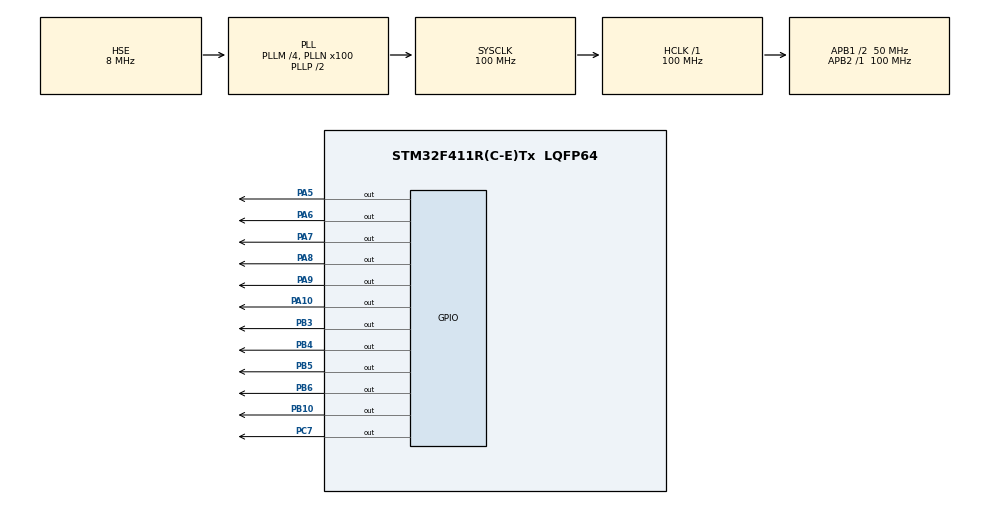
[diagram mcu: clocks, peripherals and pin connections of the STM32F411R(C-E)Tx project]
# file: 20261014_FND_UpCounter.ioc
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Mcu.Family=STM32F4
Mcu.Name=STM32F411R(C-E)Tx
Mcu.Package=LQFP64
NVIC.PriorityGroup=NVIC_PRIORITYGROUP_4
PA10.Signal=GPIO_Output
PA5.Signal=GPIO_Output
PA6.Signal=GPIO_Output
PA7.Signal=GPIO_Output
PA8.Signal=GPIO_Output
PA9.Signal=GPIO_Output
PB10.Signal=GPIO_Output
PB3.Signal=GPIO_Output
PB4.Signal=GPIO_Output
PB5.Signal=GPIO_Output
PB6.Signal=GPIO_Output
PC7.Signal=GPIO_Output
PH0\ -\ OSC_IN.Mode=HSE-External-Oscillator
PH0\ -\ OSC_IN.Signal=RCC_OSC_IN
PH1\ -\ OSC_OUT.Mode=HSE-External-Oscillator
PH1\ -\ OSC_OUT.Signal=RCC_OSC_OUT
ProjectManager.HeapSize=0x200
ProjectManager.StackSize=0x400
ProjectManager.TargetToolchain=STM32CubeIDE
RCC.48MHZClocksFreq_Value=50000000
RCC.AHBFreq_Value=100000000
RCC.APB1CLKDivider=RCC_HCLK_DIV2
RCC.APB1Freq_Value=50000000
RCC.APB1TimFreq_Value=100000000
RCC.APB2Freq_Value=100000000
RCC.APB2TimFreq_Value=100000000
RCC.CortexFreq_Value=100000000
RCC.HCLKFreq_Value=100000000
RCC.HSE_VALUE=8000000
RCC.HSI_VALUE=16000000
RCC.LSE_VALUE=32768
RCC.PLLM=4
RCC.PLLN=100
RCC.PLLSourceVirtual=RCC_PLLSOURCE_HSE
RCC.SYSCLKFreq_VALUE=100000000
RCC.SYSCLKSource=RCC_SYSCLKSOURCE_PLLCLK
RCC.VCOOutputFreq_Value=200000000
board=custom

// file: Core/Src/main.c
/* USER CODE BEGIN Header */
/**
 ******************************************************************************
 * @file           : main.c
 * @brief          : Main program body
 ******************************************************************************
 * @attention
 *
 * Copyright (c) 2026 STMicroelectronics.
 * All rights reserved.
 *
 * This software is licensed under terms that can be found in the LICENSE file
 * in the root directory of this software component.
 * If no LICENSE file comes with this software, it is provided AS-IS.
 *
 ******************************************************************************
 */
/* USER CODE END Header */
#include "main.h"

/* USER CODE BEGIN Includes */
#include "driver/fnd/fnd.h"
/* USER CODE END Includes */

void SystemClock_Config(void);
static void MX_GPIO_Init(void);

int main(void)
{

	/* USER CODE BEGIN 1 */

	/*
	seg_port_t seg_font[8] = {

			{GPIOA, GPIO_PIN_6},
			{GPIOA, GPIO_PIN_9},
			{GPIOB, GPIO_PIN_5},
			{GPIOB, GPIO_PIN_10},
			{GPIOA, GPIO_PIN_8},
			{GPIOA, GPIO_PIN_7},
			{GPIOB, GPIO_PIN_3},
			{GPIOB, GPIO_PIN_4}
	};

	int seg_font_data[10][8] = {
			{1, 1, 1, 1, 1, 1, 0, 0}, // 0
			{0, 1, 1, 0, 0, 0, 0, 0}, // 1
			{1, 1, 0, 1, 1, 0, 1, 0}, // 2
			{1, 1, 1, 1, 0, 0, 1, 0}, // 3
			{0, 1, 1, 0, 0, 1, 1, 0}, // 4
			{1, 0, 1, 1, 0, 1, 1, 0}, // 5
			{1, 0, 1, 1, 1, 1, 1, 0}, // 6
			{1, 1, 1, 0, 0, 0, 0, 0}, // 7
			{1, 1, 1, 1, 1, 1, 1, 0}, // 8
			{1, 1, 1, 1, 0, 1, 1, 0}, // 9
	};
	*/

	/* USER CODE END 1 */

	/* MCU Configuration--------------------------------------------------------*/

	/* Reset of all peripherals, Initializes the Flash interface and the Systick. */
	HAL_Init();

	/* Configure the system clock */
	SystemClock_Config();

	/* Initialize all configured peripherals */
	MX_GPIO_Init();

	/* Infinite loop */
	/* USER CODE BEGIN WHILE */
	uint16_t counter = 0;
	uint32_t prevTime = 0;

	while (1)
	{
		fnd_show_number(counter);

		if (HAL_GetTick() - prevTime > 100 ){
			prevTime = HAL_GetTick();

			if (counter == 9999) {
				counter = 0;
			}
			else {
				counter++;
			}
		}

		/* USER CODE END WHILE */

	}
}

void SystemClock_Config(void)
{
	RCC_OscInitTypeDef RCC_OscInitStruct = {0};
	RCC_ClkInitTypeDef RCC_ClkInitStruct = {0};

	/** Configure the main internal regulator output voltage
	 */
	__HAL_RCC_PWR_CLK_ENABLE();
	__HAL_PWR_VOLTAGESCALING_CONFIG(PWR_REGULATOR_VOLTAGE_SCALE1);

	/** Initializes the RCC Oscillators according to the specified parameters
	 * in the RCC_OscInitTypeDef structure.
	 */
	RCC_OscInitStruct.OscillatorType = RCC_OSCILLATORTYPE_HSE;
	RCC_OscInitStruct.HSEState = RCC_HSE_ON;
	RCC_OscInitStruct.PLL.PLLState = RCC_PLL_ON;
	RCC_OscInitStruct.PLL.PLLSource = RCC_PLLSOURCE_HSE;
	RCC_OscInitStruct.PLL.PLLM = 4;
	RCC_OscInitStruct.PLL.PLLN = 100;
	RCC_OscInitStruct.PLL.PLLP = RCC_PLLP_DIV2;
	RCC_OscInitStruct.PLL.PLLQ = 4;
	if (HAL_RCC_OscConfig(&RCC_OscInitStruct) != HAL_OK)
	{
		Error_Handler();
	}

	/** Initializes the CPU, AHB and APB buses clocks
	 */
	RCC_ClkInitStruct.ClockType = RCC_CLOCKTYPE_HCLK|RCC_CLOCKTYPE_SYSCLK
			|RCC_CLOCKTYPE_PCLK1|RCC_CLOCKTYPE_PCLK2;
	RCC_ClkInitStruct.SYSCLKSource = RCC_SYSCLKSOURCE_PLLCLK;
	RCC_ClkInitStruct.AHBCLKDivider = RCC_SYSCLK_DIV1;
	RCC_ClkInitStruct.APB1CLKDivider = RCC_HCLK_DIV2;
	RCC_ClkInitStruct.APB2CLKDivider = RCC_HCLK_DIV1;

	if (HAL_RCC_ClockConfig(&RCC_ClkInitStruct, FLASH_LATENCY_3) != HAL_OK)
	{
		Error_Handler();
	}
}

static void MX_GPIO_Init(void)
{
	GPIO_InitTypeDef GPIO_InitStruct = {0};

	/* GPIO Ports Clock Enable */
	__HAL_RCC_GPIOH_CLK_ENABLE();
	__HAL_RCC_GPIOA_CLK_ENABLE();
	__HAL_RCC_GPIOB_CLK_ENABLE();
	__HAL_RCC_GPIOC_CLK_ENABLE();

	/*Configure GPIO pin Output Level */
	HAL_GPIO_WritePin(GPIOA, GPIO_PIN_5|GPIO_PIN_6|GPIO_PIN_7|GPIO_PIN_8
			|GPIO_PIN_9|GPIO_PIN_10, GPIO_PIN_RESET);

	/*Configure GPIO pin Output Level */
	HAL_GPIO_WritePin(GPIOB, GPIO_PIN_10|GPIO_PIN_3|GPIO_PIN_4|GPIO_PIN_5
			|GPIO_PIN_6, GPIO_PIN_RESET);

	/*Configure GPIO pin Output Level */
	HAL_GPIO_WritePin(GPIOC, GPIO_PIN_7, GPIO_PIN_RESET);

	/*Configure GPIO pins : PA5 PA6 PA7 PA8
                           PA9 PA10 */
	GPIO_InitStruct.Pin = GPIO_PIN_5|GPIO_PIN_6|GPIO_PIN_7|GPIO_PIN_8
			|GPIO_PIN_9|GPIO_PIN_10;
	GPIO_InitStruct.Mode = GPIO_MODE_OUTPUT_PP;
	GPIO_InitStruct.Pull = GPIO_NOPULL;
	GPIO_InitStruct.Speed = GPIO_SPEED_FREQ_LOW;
	HAL_GPIO_Init(GPIOA, &GPIO_InitStruct);

	/*Configure GPIO pins : PB10 PB3 PB4 PB5
                           PB6 */
	GPIO_InitStruct.Pin = GPIO_PIN_10|GPIO_PIN_3|GPIO_PIN_4|GPIO_PIN_5
			|GPIO_PIN_6;
	GPIO_InitStruct.Mode = GPIO_MODE_OUTPUT_PP;
	GPIO_InitStruct.Pull = GPIO_NOPULL;
	GPIO_InitStruct.Speed = GPIO_SPEED_FREQ_LOW;
	HAL_GPIO_Init(GPIOB, &GPIO_InitStruct);

	/*Configure GPIO pin : PC7 */
	GPIO_InitStruct.Pin = GPIO_PIN_7;
	GPIO_InitStruct.Mode = GPIO_MODE_OUTPUT_PP;
	GPIO_InitStruct.Pull = GPIO_NOPULL;
	GPIO_InitStruct.Speed = GPIO_SPEED_FREQ_LOW;
	HAL_GPIO_Init(GPIOC, &GPIO_InitStruct);

}

void Error_Handler(void)
{
	__disable_irq();
	while (1)
	{
	}
}
